# WKUP_PLLCTRL0 register map
Vendor: Texas Instruments
Peripheral module from a debugger description file (folder am65x).
Registers are 32-bit, read-write, reset 0x0 unless marked. A register's access mark holds for its fields unless they carry their own. Offsets are as the file gives them; lines under a group give offsets from that group; [hi:lo] are bit positions; {n}, {i} and the like mark numbered series; 'fields as' and 'values as' point back to an identical list; <NAME> marks a mode.

## WKUP_PLLCTRL0
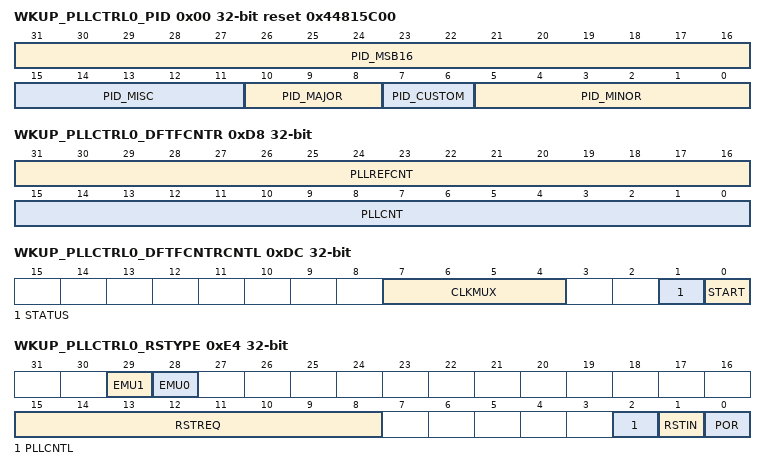
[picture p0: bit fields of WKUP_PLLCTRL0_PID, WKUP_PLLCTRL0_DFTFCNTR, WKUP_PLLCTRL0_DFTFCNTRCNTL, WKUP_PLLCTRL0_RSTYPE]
0x00 WKUP_PLLCTRL0_PID ro reset 0x44815C00 — Peripheral Identification Register The peripheral identification register is a constant register that contains the ID and ID revision number for that module. The stores version information used to identify the module.
  [31:16] PID_MSB16
  [15:11] PID_MISC — RTL Version.
  [10:8] PID_MAJOR — Major Revision.
  [7:6] PID_CUSTOM — Indicates a special version for a particular device.
  [5:0] PID_MINOR — Minor Revision.
0xD0 WKUP_PLLCTRL0_SHIFTDIV — Shift Clock Divider Register This register is used in burnin mode. It contains the divider value for the burnin shift clock. This value is typically scanned in by the config scan chain. This register can be read/writable by software.
  [7:0] DIV_VALUE — Divider value
0xD4 WKUP_PLLCTRL0_CS0 — PLL Catscan Register This register is used to write catscan registers.
  [0] CS_CLK_START — Starts catscan counter that when reaches 0 will stop the clocks.
0xD8 WKUP_PLLCTRL0_DFTFCNTR — DFT Frequency Counter Register This register is the frequency counter register. It is used to validate the pll. The function is to have a 16-bit down counter for the pll input clock and a 16-bit up counter for the pll clock,or divided clock, to determine actual pll multiply factor. The down counter will stop at 0 and stop the up counter, if down counter is 0 it will not count and will stop the other counter immediately. The up counter will count to ffff and stop, it will also stop the down counter when this happens. If started at ffff will not count and will stop the other counter immediately. The start bit being set to 1 starts the counting. Due to synchronizing effects the counters will be off by a couple cycles when they start or stop.
  [31:16] PLLREFCNT — Counter values for pll refclock(down counter), clock source always pll input clock.
  [15:0] PLLCNT — Counter values for pll derived clock(up counter), counting clock configurable, see DFTCNTRCNTL.
0xDC WKUP_PLLCTRL0_DFTFCNTRCNTL access per field — DFT Frequency Counter Control Register This register controls the start of the frequency counters via the start bit. The status bit is not meaningfull if the start bit is not enabled. If the start bit is enabled the status bit indicates if the counters have stopped and can be read reliably.
  [7:4] CLKMUX rw — Clock source used by pll counter.
  [1] STATUS ro — Status of counter
  [0] START rw — Enable counter
0xE0 WKUP_PLLCTRL0_FUSERR ro reset not defined — E-fusefarm Error Register This register is used to capture the C027 fusefarm outputs error code efc_error[4:0] through signal ferror_pi[4:0]. Users should check for any fusefarm error (by reading this register) during device software initialization.
  [4:0] ERR — Fusefarm Error Output
0xE4 WKUP_PLLCTRL0_RSTYPE ro reset not defined — Reset Type Status Register This register latches the cause of the last reset. If multiple reset sources are asserted simultaneously, this register records whichever reset source that de-asserts last. If multiple reset sources are asserted and de-asserted simultaneously, this register latches the highest priority reset source.
  [29] EMU1 — 0 = reset was not the last reset to occur
  [28] EMU0 — Emulation chip 0 reset
  [15:8] RSTREQ — Chip Reset request
  [2] PLLCNTL — Pll mmr controlled software Reset
  [1] RSTIN — External Warm Reset device pin
  [0] POR — Power On Reset
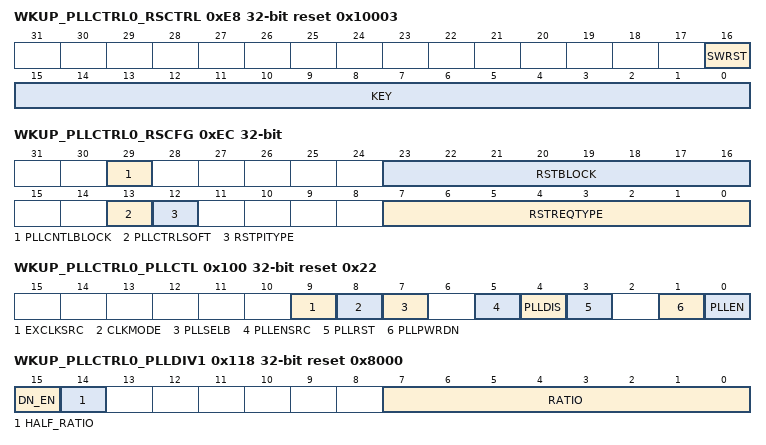
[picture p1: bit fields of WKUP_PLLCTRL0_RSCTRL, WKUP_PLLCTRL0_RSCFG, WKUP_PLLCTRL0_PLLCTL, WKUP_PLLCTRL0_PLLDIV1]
0xE8 WKUP_PLLCTRL0_RSCTRL reset 0x10003 — Reset Control Register This register contains a key that enables writes to the upper part of the . This key also enables writes to the and registers. The key value is 0x5a69. A valid key will be stored as 0x000c, any other key value is invalid. When the , or the is written the key is invalidated. So every write must be setup with a valid key being written prior.
  [16] SWRST — Software reset
  [15:0] KEY — Key used to enable writes to and
0xEC WKUP_PLLCTRL0_RSCFG — Reset Configuration Register This register is used to configure what type of reset is generated, chip_0_rst_po_n and chip_1_rst_po_n or just chip_1_rst_pi_n. It is also used to set which reset is blocked. When chip_0_rst_n_po is set both chip_0_rst_n_po and chip_1_rst_n_po are asserted. When chip_1_rst_n_po is set only chip_1_rst_n_po is asserted.
  [29] PLLCNTLBLOCK — Reset only on POR, blocks reset from affecting all pll_ctrll mmr registers.
  [23:16] RSTBLOCK — pll_ctrl input reset_req_pi_n[N]
  [13] PLLCTRLSOFT — Pll_ctrl software reset
  [12] RSTPITYPE — Pll_ctrl input reset_n_pi(device warm reset) behaves like
  [7:0] RSTREQTYPE — pll_ctrl input reset_req_pi_n[N]
0xF0 WKUP_PLLCTRL0_RSISO — Reset Isolation Register The reset isolation register is used to indicate which sysclk_po clocks must maintain their frequency without pausing through non-por resets. Setting any of these bit effectively blocks all pll_ctrl mmr’s in order to maintain current values of pll multiplier, divide ratio’s and etc. The pll_ctrl output pll_ctrl_rst_n_po will not be blocked by the isolation register setting. The slave pll_ctrl will need to block reset there with it’s reset iso registers.
  [15:0] SYSCLKISO — Indicates sysclk_po[N] is reset isolation, effectively also blocks reset to all pll_ctrl mmr registers
0x100 WKUP_PLLCTRL0_PLLCTL reset 0x22 (reset mask 0x2A3) — PLL Control Register The register contains bits to control PLL operations. Note that PLLs are placed outside of the PLLCTRL module.
  [9] EXCLKSRC — Selects between using bypass clock or an external clock source.
  [8] CLKMODE — Reference Clock Selection.
  [7] PLLSELB — Selects PLL A versus PLL B.
  [5] PLLENSRC — PLLEN Mux Control Source
  [4] PLLDIS — Asserts DISABLE to PLL if Supported
  [3] PLLRST — Asserts RESET to PLL if Supported.
  [1] PLLPWRDN — Selects PLL Power Down for the PLL selected by PLLSELB.
  [0] PLLEN — PLL Mode Enable
0x110 WKUP_PLLCTRL0_PLLM reset not defined — PLL Multiplier Control Register This register configures the multiplier control to the PLL.
  [7:0] _ — PLL Multiplier Select
0x118 WKUP_PLLCTRL0_PLLDIV1 access per field reset 0x8000 (reset mask 0xC000) — PLL Controller Divider 1 Register for SYSCLK1 This register controls value of the divider 1 for SYSCLK1. It divides down the sysrefclk (SYSCLK reference clock from either the BYPASS or PLL path). The “n” in the following table should be replaced with the appropriate divider number (e.g. use D1EN for and SYSCLK1).
  [15] DN_EN ro — Divider Dn Enable
  [14] HALF_RATIO rw — Ratio is in half steps.
  [7:0] RATIO rw — Divider Dn Ratio (SYSCLKn divider)
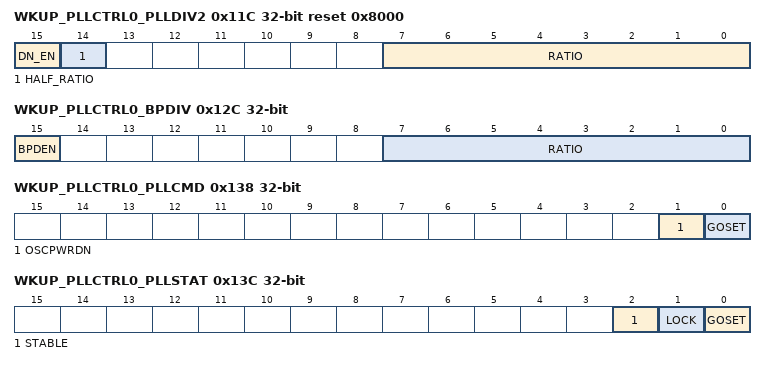
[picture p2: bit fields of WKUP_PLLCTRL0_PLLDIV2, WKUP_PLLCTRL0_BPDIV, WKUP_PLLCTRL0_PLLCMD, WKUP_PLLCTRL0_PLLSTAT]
0x11C WKUP_PLLCTRL0_PLLDIV2 access per field reset 0x8000 (reset mask 0xC000) — PLL Controller Divider 2 Register for SYSCLK2 This register controls value of the divider 2 for SYSCLK2. It divides down the sysrefclk (SYSCLK reference clock from either the BYPASS or PLL path). The “n” in the following table should be replaced with the appropriate divider number (e.g. use D1EN for and SYSCLK1).
  fields as WKUP_PLLCTRL0_PLLDIV1
0x12C WKUP_PLLCTRL0_BPDIV reset not defined — Bypass Divider Register for SYSCLKBP This register controls value of the BPDIV for SYSCLKBP. It divides down the refclk (CLKIN or OSCIN).
  [15] BPDEN — Bypass Divider Enable
  [7:0] RATIO — Bypass Divider Ratio (SYSCLKBP divider)
0x130 WKUP_PLLCTRL0_WAKEUP — Wakeup Register This register controls whether different events in the system are enabled to wake up the device after entering oscillator power down through OSCPWRDN.
  [15:0] WKEN — Input wakeupin_i[0 to 15].
0x138 WKUP_PLLCTRL0_PLLCMD — PLL Controller Command Register The PLL Controller Command Register contains command bits for various PLLCTRL operations. The register bits always read back what was previously written, but no action should be initiated based on a read. They are not self-modified by the PLLCTRL except through reset, where the bits return to default. A write of 1 to a defined bit triggers the action, a write of 0 is ignored. The status of the command can be viewed in the register.
  [1] OSCPWRDN — Oscillator Power Down Command
  [0] GOSET — GO bit for SYSCLKx phase alignment.
0x13C WKUP_PLLCTRL0_PLLSTAT ro (reset mask 0x3) — PLL Controller Status Register The fields in this register shows the PLL Controller status.
  [2] STABLE — OSCIN Stable
  [1] LOCK — PLL Core STATUS
  [0] GOSET — Reflects the status of GO transition.
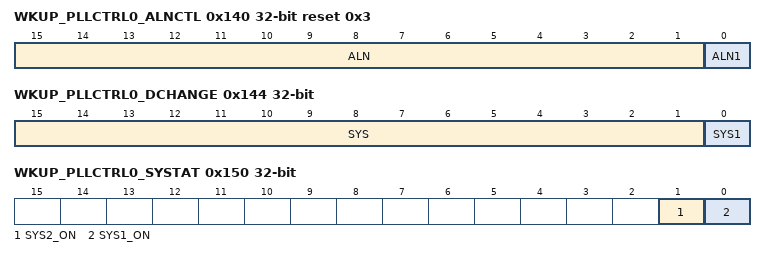
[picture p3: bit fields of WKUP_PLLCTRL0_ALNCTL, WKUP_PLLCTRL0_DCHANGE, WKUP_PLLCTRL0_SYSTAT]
0x140 WKUP_PLLCTRL0_ALNCTL reset 0x3 — PLL Controller Clock Align Control Register The bits in this register correspond to the SYSCLK[x-1]. For example, bit 0 corresponds to SYSCLK1, bit 1 corresponds to SYSCLK2…etc. Only bit fields corresponding to existing SYSCLKx are defined. For example, bit 31 is not defined because SYSCLK32 does not exist. By setting the ALN bits, the selected SYSCLKx will always be phase aligned to other clocks also selected in this register. This is useful for aligning selected clocks for these operations: GO operation: Align selected clocks after changing divider ratios Clock Gating Operation: Align selected clocks before starting a clock-gated SYSCLK again It is user’s responsibility to ensure that is not written to when GO operation is in progress (i.e. when .GOSTAT = 1). Otherwise operation is undefined.
  [15:1] ALN — SYSCLKx needs to be aligned with other clocks selected in this register.
  [0] ALN1 — SYSCLK1 needs to be aligned with other clocks selected in this register.
0x144 WKUP_PLLCTRL0_DCHANGE ro — PLLDIV Divider Ratio Change Status Register The register bits in this register correspond to the SYSCLKx. For example, bit SYS1 corresponds to SYSCLK1. Only bit fields corresponding to existing SYSCLKx are defined. For example, bit 31 is not defined because SYSCLK32 does not exist. Whenever a different ratio is written to the PLLDIV[] registers, the PLLCTRL flags the change in the status register. During GO operation, the PLLCTRL will only change the divide ratio of the SYSCLK with the bit set in . Note that register determines if that clock also needs to be aligned to other clocks.
  [15:1] SYS — SYSCLKx divide ratio has been modified.
  [0] SYS1 — SYSCLK1 divide ratio has been modified.
0x150 WKUP_PLLCTRL0_SYSTAT ro reset not defined — SYSCLK Status Register This register shows the enable/disable status of SYSCLKx. Clock gating is controlled in three ways - register setting in PLLDIVx, module input, or DFT/CATScan control. Note that this register does not reflect the temporary clock pause status to align clocks coming out of reset, clock-gating, or SYSCLK divide ratio change (GO operation).
  [1] SYS2_ON — SYSCLK2 on
  [0] SYS1_ON — SYSCLK1 on
